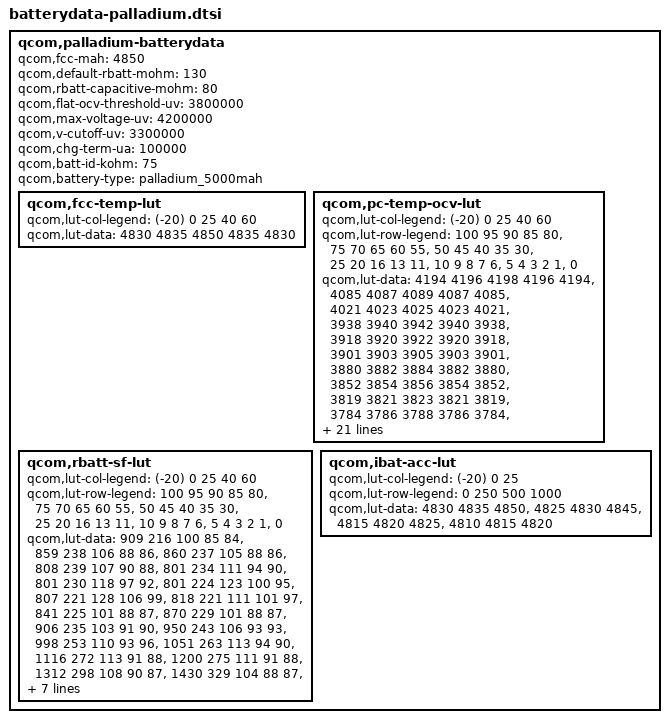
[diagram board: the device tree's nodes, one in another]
/* Copyright (c) 2013-2014, The Linux Foundation. All rights reserved.
 *
 * This program is free software; you can redistribute it and/or modify
 * it under the terms of the GNU General Public License version 2 and
 * only version 2 as published by the Free Software Foundation.
 *
 * This program is distributed in the hope that it will be useful,
 * but WITHOUT ANY WARRANTY; without even the implied warranty of
 * MERCHANTABILITY or FITNESS FOR A PARTICULAR PURPOSE.  See the
 * GNU General Public License for more details.
 */

qcom,palladium-batterydata {
        qcom,fcc-mah = <4850>;       // zztg 20201126
	qcom,default-rbatt-mohm = <130>;
	qcom,rbatt-capacitive-mohm = <80>;
	qcom,flat-ocv-threshold-uv = <3800000>;
	qcom,max-voltage-uv = <4200000>;
	qcom,v-cutoff-uv = <3300000>;	
	qcom,chg-term-ua = <100000>;
	qcom,batt-id-kohm = <75>;
	qcom,battery-type = "palladium_5000mah";

        qcom,fcc-temp-lut {
                qcom,lut-col-legend = <(-20) 0 25 40 60>;
                qcom,lut-data = <4830 4835 4850 4835 4830>;
        };

	qcom,pc-temp-ocv-lut {
		qcom,lut-col-legend = <(-20) 0 25 40 60>;
		qcom,lut-row-legend = <100 95 90 85 80>,
				<75 70 65 60 55>,
				<50 45 40 35 30>,
				<25 20 16 13 11>,
				<10 9 8 7 6>,
				<5 4 3 2 1>,
				<0>;
		qcom,lut-data = <4194 4196 4198 4196 4194>,
				<4085 4087 4089 4087 4085>,
				<4021 4023 4025 4023 4021>,
				<3938 3940 3942 3940 3938>,
				<3918 3920 3922 3920 3918>,
				<3901 3903 3905 3903 3901>,
				<3880 3882 3884 3882 3880>,
				<3852 3854 3856 3854 3852>,
				<3819 3821 3823 3821 3819>,
				<3784 3786 3788 3786 3784>,
				<3761 3763 3765 3763 3761>,
				<3751 3753 3755 3753 3751>,
				<3746 3748 3750 3748 3746>,
				<3741 3743 3745 3743 3741>,
				<3736 3738 3740 3738 3736>,
				<3732 3734 3736 3734 3732>,
				<3724 3726 3728 3726 3724>,
				<3708 3710 3712 3710 3708>,
				<3694 3696 3698 3696 3694>,
				<3681 3683 3685 3683 3681>,
				<3670 3672 3674 3672 3670>,
				<3646 3648 3650 3648 3646>,
				<3619 3621 3623 3621 3619>,
				<3588 3590 3592 3590 3588>,
				<3552 3554 3556 3554 3552>,
				<3511 3513 3515 3513 3511>,
				<3465 3467 3469 3467 3465>,
				<3447 3449 3451 3449 3447>,
				<3424 3426 3428 3426 3424>,
				<3409 3411 3413 3411 3409>,
				<3400 3400 3400 3400 3400>;					

	};

	qcom,rbatt-sf-lut {
		qcom,lut-col-legend = <(-20) 0 25 40 60>;
		qcom,lut-row-legend = <100 95 90 85 80>,
				<75 70 65 60 55>,
				<50 45 40 35 30>,
				<25 20 16 13 11>,
				<10 9 8 7 6>,
				<5 4 3 2 1>,
				<0>;
		qcom,lut-data = <909 216 100 85 84>,
				<859 238 106 88 86>,
				<860 237 105 88 86>,
				<808 239 107 90 88>,
				<801 234 111 94 90>,
				<801 230 118 97 92>,
				<801 224 123 100 95>,
				<807 221 128 106 99>,
				<818 221 111 101 97>,
				<841 225 101 88 87>,
				<870 229 101 88 87>,
				<906 235 103 91 90>,
				<950 243 106 93 93>,
				<998 253 110 93 96>,
				<1051 263 113 94 90>,
				<1116 272 113 91 88>,
				<1200 275 111 91 88>,
				<1312 298 108 90 87>,
				<1430 329 104 88 87>,
				<1484 351 107 91 89>,
				<1446 345 110 93 90>,
				<1398 344 112 94 90>,
				<1466 358 115 96 91>,
				<1490 357 117 96 90>,
				<1589 365 117 94 89>,
				<1828 379 111 91 88>,
				<2151 399 111 93 91>,
				<2621 436 117 98 95>,
				<3404 496 130 106 100>,
				<8212 616 150 1906 134>,
				<135251 124940 59087 49820 29672>;
	};

	qcom,ibat-acc-lut {
		qcom,lut-col-legend = <(-20) 0 25>;
		qcom,lut-row-legend = <0 250 500 1000>;
		qcom,lut-data = <4830 4835 4850>,
				<4825 4830 4845>,
				<4815 4820 4825>,
				<4810 4815 4820>;
	};
};
